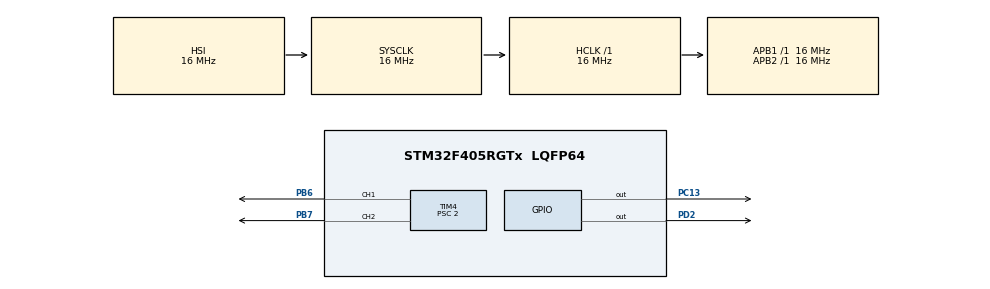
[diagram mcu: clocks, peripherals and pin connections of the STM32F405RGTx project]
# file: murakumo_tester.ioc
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Mcu.Family=STM32F4
Mcu.Name=STM32F405RGTx
Mcu.Package=LQFP64
NVIC.PriorityGroup=NVIC_PRIORITYGROUP_4
PA13.Mode=Serial_Wire
PA13.Signal=SYS_JTMS-SWDIO
PA14.Mode=Serial_Wire
PA14.Signal=SYS_JTCK-SWCLK
PB6.Signal=S_TIM4_CH1
PB7.Signal=S_TIM4_CH2
PC13-ANTI_TAMP.Signal=GPIO_Output
PD2.Signal=GPIO_Output
ProjectManager.HeapSize=0x200
ProjectManager.StackSize=0x400
ProjectManager.TargetToolchain=STM32CubeIDE
RCC.AHBFreq_Value=16000000
RCC.APB1Freq_Value=16000000
RCC.APB2Freq_Value=16000000
RCC.CortexFreq_Value=16000000
RCC.HSE_VALUE=25000000
RCC.HSI_VALUE=16000000
RCC.LSE_VALUE=32768
RCC.SYSCLKFreq_VALUE=16000000
RCC.VCOOutputFreq_Value=192000000
SH.S_TIM4_CH1.0=TIM4_CH1,PWM Generation1 CH1
SH.S_TIM4_CH2.0=TIM4_CH2,PWM Generation2 CH2
TIM4.Channel-PWM\ Generation1\ CH1=TIM_CHANNEL_1
TIM4.Channel-PWM\ Generation2\ CH2=TIM_CHANNEL_2
TIM4.Period=999
TIM4.Prescaler=2
board=custom

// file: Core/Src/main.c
/* USER CODE BEGIN Header */
/**
  ******************************************************************************
  * @file           : main.c
  * @brief          : Main program body
  ******************************************************************************
  * @attention
  *
  * Copyright (c) 2023 STMicroelectronics.
  * All rights reserved.
  *
  * This software is licensed under terms that can be found in the LICENSE file
  * in the root directory of this software component.
  * If no LICENSE file comes with this software, it is provided AS-IS.
  *
  ******************************************************************************
  */
/* USER CODE END Header */
#include "main.h"

TIM_HandleTypeDef htim4;

void SystemClock_Config(void);
static void MX_GPIO_Init(void);
static void MX_TIM4_Init(void);

int main(void)
{

  /* MCU Configuration--------------------------------------------------------*/

  /* Reset of all peripherals, Initializes the Flash interface and the Systick. */
  HAL_Init();

  /* USER CODE BEGIN Init */

  motor_init();

  /* USER CODE END Init */

  /* Configure the system clock */
  SystemClock_Config();

  /* Initialize all configured peripherals */
  MX_GPIO_Init();
  MX_TIM4_Init();
  /* USER CODE BEGIN 2 */

  motor_start();

  int out = 100;

  motor_set(out, out);
  /* USER CODE END 2 */

  /* Infinite loop */
  while (1)
  {

	  HAL_Delay(1000);

  }
}

void SystemClock_Config(void)
{
  RCC_OscInitTypeDef RCC_OscInitStruct = {0};
  RCC_ClkInitTypeDef RCC_ClkInitStruct = {0};

  /** Configure the main internal regulator output voltage
  */
  __HAL_RCC_PWR_CLK_ENABLE();
  __HAL_PWR_VOLTAGESCALING_CONFIG(PWR_REGULATOR_VOLTAGE_SCALE1);
  /** Initializes the RCC Oscillators according to the specified parameters
  * in the RCC_OscInitTypeDef structure.
  */
  RCC_OscInitStruct.OscillatorType = RCC_OSCILLATORTYPE_HSI;
  RCC_OscInitStruct.HSIState = RCC_HSI_ON;
  RCC_OscInitStruct.HSICalibrationValue = RCC_HSICALIBRATION_DEFAULT;
  RCC_OscInitStruct.PLL.PLLState = RCC_PLL_NONE;
  if (HAL_RCC_OscConfig(&RCC_OscInitStruct) != HAL_OK)
  {
    Error_Handler();
  }
  /** Initializes the CPU, AHB and APB buses clocks
  */
  RCC_ClkInitStruct.ClockType = RCC_CLOCKTYPE_HCLK|RCC_CLOCKTYPE_SYSCLK
                              |RCC_CLOCKTYPE_PCLK1|RCC_CLOCKTYPE_PCLK2;
  RCC_ClkInitStruct.SYSCLKSource = RCC_SYSCLKSOURCE_HSI;
  RCC_ClkInitStruct.AHBCLKDivider = RCC_SYSCLK_DIV1;
  RCC_ClkInitStruct.APB1CLKDivider = RCC_HCLK_DIV1;
  RCC_ClkInitStruct.APB2CLKDivider = RCC_HCLK_DIV1;

  if (HAL_RCC_ClockConfig(&RCC_ClkInitStruct, FLASH_LATENCY_0) != HAL_OK)
  {
    Error_Handler();
  }
}

static void MX_TIM4_Init(void)
{

  TIM_MasterConfigTypeDef sMasterConfig = {0};
  TIM_OC_InitTypeDef sConfigOC = {0};

  htim4.Instance = TIM4;
  htim4.Init.Prescaler = 2;
  htim4.Init.CounterMode = TIM_COUNTERMODE_UP;
  htim4.Init.Period = 999;
  htim4.Init.ClockDivision = TIM_CLOCKDIVISION_DIV1;
  htim4.Init.AutoReloadPreload = TIM_AUTORELOAD_PRELOAD_DISABLE;
  if (HAL_TIM_PWM_Init(&htim4) != HAL_OK)
  {
    Error_Handler();
  }
  sMasterConfig.MasterOutputTrigger = TIM_TRGO_RESET;
  sMasterConfig.MasterSlaveMode = TIM_MASTERSLAVEMODE_DISABLE;
  if (HAL_TIMEx_MasterConfigSynchronization(&htim4, &sMasterConfig) != HAL_OK)
  {
    Error_Handler();
  }
  sConfigOC.OCMode = TIM_OCMODE_PWM1;
  sConfigOC.Pulse = 0;
  sConfigOC.OCPolarity = TIM_OCPOLARITY_HIGH;
  sConfigOC.OCFastMode = TIM_OCFAST_DISABLE;
  if (HAL_TIM_PWM_ConfigChannel(&htim4, &sConfigOC, TIM_CHANNEL_1) != HAL_OK)
  {
    Error_Handler();
  }
  if (HAL_TIM_PWM_ConfigChannel(&htim4, &sConfigOC, TIM_CHANNEL_2) != HAL_OK)
  {
    Error_Handler();
  }
  HAL_TIM_MspPostInit(&htim4);

}

static void MX_GPIO_Init(void)
{
  GPIO_InitTypeDef GPIO_InitStruct = {0};

  /* GPIO Ports Clock Enable */
  __HAL_RCC_GPIOC_CLK_ENABLE();
  __HAL_RCC_GPIOA_CLK_ENABLE();
  __HAL_RCC_GPIOD_CLK_ENABLE();
  __HAL_RCC_GPIOB_CLK_ENABLE();

  /*Configure GPIO pin Output Level */
  HAL_GPIO_WritePin(GPIOC, GPIO_PIN_13, GPIO_PIN_RESET);

  /*Configure GPIO pin Output Level */
  HAL_GPIO_WritePin(GPIOD, GPIO_PIN_2, GPIO_PIN_RESET);

  /*Configure GPIO pin : PC13 */
  GPIO_InitStruct.Pin = GPIO_PIN_13;
  GPIO_InitStruct.Mode = GPIO_MODE_OUTPUT_PP;
  GPIO_InitStruct.Pull = GPIO_NOPULL;
  GPIO_InitStruct.Speed = GPIO_SPEED_FREQ_LOW;
  HAL_GPIO_Init(GPIOC, &GPIO_InitStruct);

  /*Configure GPIO pin : PD2 */
  GPIO_InitStruct.Pin = GPIO_PIN_2;
  GPIO_InitStruct.Mode = GPIO_MODE_OUTPUT_PP;
  GPIO_InitStruct.Pull = GPIO_NOPULL;
  GPIO_InitStruct.Speed = GPIO_SPEED_FREQ_LOW;
  HAL_GPIO_Init(GPIOD, &GPIO_InitStruct);

}

void Error_Handler(void)
{
  __disable_irq();
  while (1)
  {
  }
}
